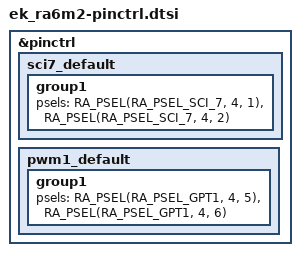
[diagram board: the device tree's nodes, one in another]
/*
 * Copyright (c) 2024 Renesas Electronics Corporation
 * SPDX-License-Identifier: Apache-2.0
 */

&pinctrl {
	sci7_default: sci7_default {
		group1 {
			/* tx rx */
			psels = <RA_PSEL(RA_PSEL_SCI_7, 4, 1)>,
			<RA_PSEL(RA_PSEL_SCI_7, 4, 2)>;
		};
	};

	pwm1_default: pwm1_default {
		group1 {
			/* GTIOC1A GTIOC1B */
			psels = <RA_PSEL(RA_PSEL_GPT1, 4, 5)>,
				<RA_PSEL(RA_PSEL_GPT1, 4, 6)>;
		};
	};
};
